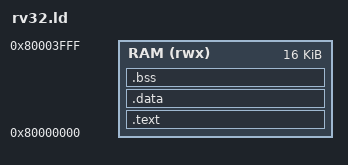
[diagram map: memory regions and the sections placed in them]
ENTRY(_start)

MEMORY
{
    RAM (rwx) : ORIGIN = 0x80000000, LENGTH = 16K
}

SECTIONS
{
    .text : { KEEP(*(.start)) *(.text*) *(.rodata*) } > RAM
    .data : { *(.data*) } > RAM
    .bss (NOLOAD) : { *(.bss*) *(COMMON) } > RAM
    . = ALIGN(16);
    _stack_top = ORIGIN(RAM) + LENGTH(RAM);
}
